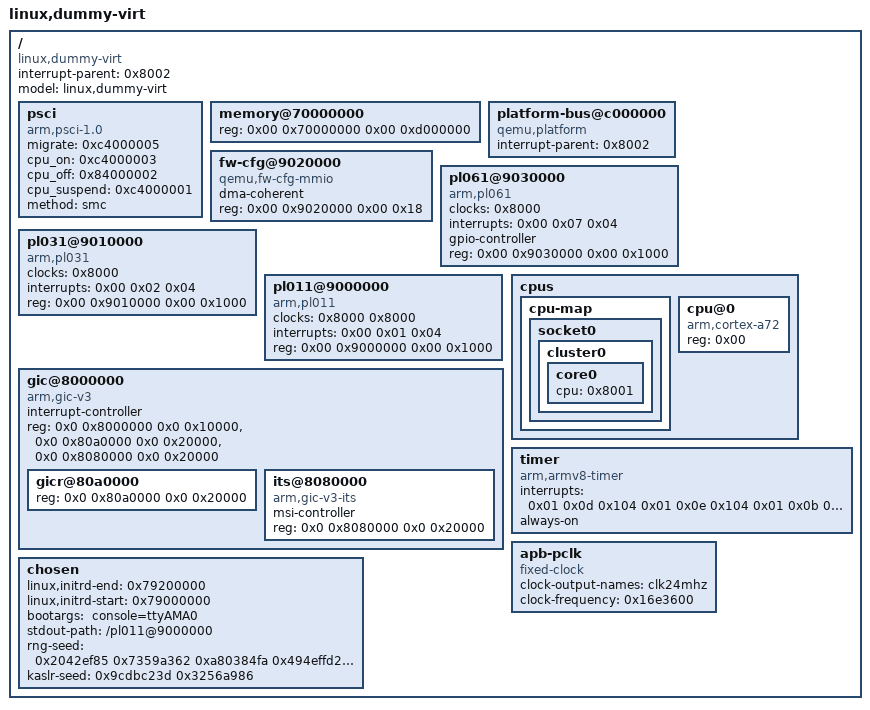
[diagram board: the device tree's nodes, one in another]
/dts-v1/;

/ {
	interrupt-parent = <0x8002>;
	model = "linux,dummy-virt";
	#size-cells = <0x02>;
	#address-cells = <0x02>;
	compatible = "linux,dummy-virt";

	psci {
		migrate = <0xc4000005>;
		cpu_on =  <0xc4000003>;
		cpu_off = <0x84000002>;
		cpu_suspend = <0xc4000001>;
		method = "smc";
		compatible = "arm,psci-1.0\0arm,psci-0.2\0arm,psci";
	};

	// ok
	memory@70000000 {
		reg = <0x00 0x70000000 0x00 0xd000000>;
		device_type = "memory";
	};

	platform-bus@c000000 {
		interrupt-parent = <0x8002>;
		ranges = <0x00 0x00 0xc000000 0x2000000>;
		#address-cells = <0x01>;
		#size-cells = <0x01>;
		compatible = "qemu,platform\0simple-bus";
	};

	fw-cfg@9020000 {
		dma-coherent;
		reg = <0x00 0x9020000 0x00 0x18>;
		compatible = "qemu,fw-cfg-mmio";
	};

	pl061@9030000 {
		phandle = <0x8004>;
		clock-names = "apb_pclk";
		clocks = <0x8000>;
		interrupts = <0x00 0x07 0x04>;
		gpio-controller;
		#gpio-cells = <0x02>;
		compatible = "arm,pl061\0arm,primecell";
		reg = <0x00 0x9030000 0x00 0x1000>;
	};

	pl031@9010000 {
		clock-names = "apb_pclk";
		clocks = <0x8000>;
		interrupts = <0x00 0x02 0x04>;
		reg = <0x00 0x9010000 0x00 0x1000>;
		compatible = "arm,pl031\0arm,primecell";
	};

	pl011@9000000 {
		clock-names = "uartclk\0apb_pclk";
		clocks = <0x8000 0x8000>;
		interrupts = <0x00 0x01 0x04>;
		reg = <0x00 0x9000000 0x00 0x1000>;
		compatible = "arm,pl011\0arm,primecell";
	};

	// gic v3
	gic@8000000 {
		compatible = "arm,gic-v3";
		#interrupt-cells = <3>;
		interrupt-controller;
		reg = <0x0 0x8000000 0x0 0x10000>,  // GICD
			<0x0 0x80a0000 0x0 0x20000>,  // GICR Redistributor base (may need adjustment)
			<0x0 0x8080000 0x0 0x20000>;  // ITS (if applicable, may need adjustment)
		phandle = <0x8002>;

		ranges;

		gicr@80a0000 {
			reg = <0x0 0x80a0000 0x0 0x20000>;
		};

		its@8080000 {
			compatible = "arm,gic-v3-its";
			msi-controller;
			reg = <0x0 0x8080000 0x0 0x20000>;
			phandle = <0x8003>;
		};
	};


	cpus {
		#size-cells = <0x00>;
		#address-cells = <0x01>;

		cpu-map {

			socket0 {

				cluster0 {

					core0 {
						cpu = <0x8001>;
					};
				};
			};
		};

		cpu@0 {
			phandle = <0x8001>;
			reg = <0x00>;
			compatible = "arm,cortex-a72";
			device_type = "cpu";
		};
	};

	timer {
		interrupts = <0x01 0x0d 0x104 0x01 0x0e 0x104 0x01 0x0b 0x104 0x01 0x0a 0x104>;
		always-on;
		compatible = "arm,armv8-timer\0arm,armv7-timer";
	};

	apb-pclk {
		phandle = <0x8000>;
		clock-output-names = "clk24mhz";
		clock-frequency = <0x16e3600>;
		#clock-cells = <0x00>;
		compatible = "fixed-clock";
	};

	chosen {
		linux,initrd-end =   <0x79200000>;
		linux,initrd-start = <0x79000000>;
		bootargs = " console=ttyAMA0";
		stdout-path = "/pl011@9000000";
		rng-seed = <0x2042ef85 0x7359a362 0xa80384fa 0x494effd2 0xd1e13e05 0xb6fae544 0xd3a19513 0x1cebc2c8>;
		kaslr-seed = <0x9cdbc23d 0x3256a986>;
	};
};
